# IMM100A register map
Vendor: Infineon; File version: 0.8.0 (Reference Manual v0.8.0)
CPU: CM0 r0p0, little endian, no MPU, no FPU, 2 interrupt priority bits
Registers are 32-bit, read-write, reset 0x0 unless marked. A register's access mark holds for its fields unless they carry their own. Offsets are from the block's base; [hi:lo] are bit positions; {n}, {i} and the like mark numbered series.

## PPB — Cortex-M0 Private Peripheral Block
Base 0xE000E000
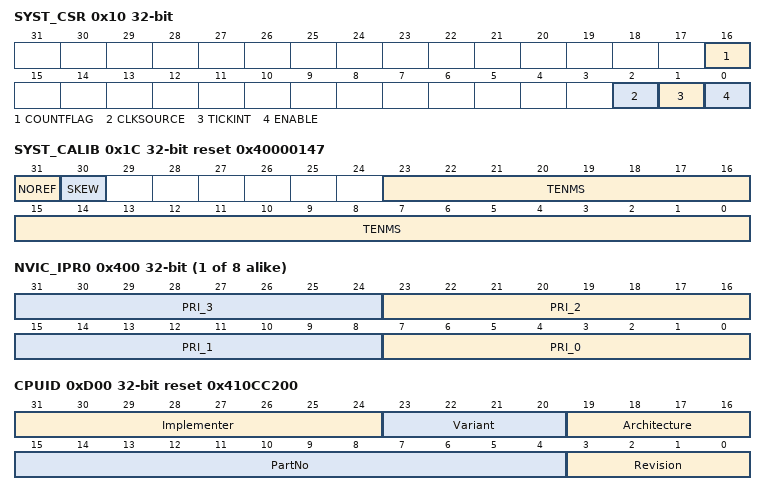
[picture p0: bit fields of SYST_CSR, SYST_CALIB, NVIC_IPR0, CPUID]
0x10 SYST_CSR — SysTick Control and Status Register
  [16] COUNTFLAG — Counter Flag
  [2] CLKSOURCE — Clock Source
    0=External clock; 1=Processor clock
  [1] TICKINT — SysTick Exception Request
    0=Counting down to zero does not assert the SysTick exception request; 1=Counting down to zero to assert the SysTick exception request
  [0] ENABLE — Counter Enable
    0=Counter disabled; 1=Counter enabled
0x14 SYST_RVR reset not defined — SysTick Reload Value Register
  [23:0] RELOAD — Reload Value
0x18 SYST_CVR reset not defined — SysTick Current Value Register
  [23:0] CURRENT — SysTick Counter Current Value
0x1C SYST_CALIB ro reset 0x40000147 — SysTick Calibration Value Register
  [31] NOREF — Reference Clock
  [30] SKEW — Clock Skew
  [23:0] TENMS — 10 Milliseconds
0x100 NVIC_ISER — Interrupt Set-enable Register
  [31:0] SETENA — Interrupt Node Set-enable
    0=Read: Interrupt node disabled. Write: No effect.; 1=Read: Interrupt node enabled. Write: Enable interrupt node
0x180 NVIC_ICER — IInterrupt Clear-enable Register
  [31:0] CLRENA — Interrupt Node Clear-enable
    0=Read: Interrupt node disabled. Write: No effect; 1=Read: Interrupt node enabled. Write: Disable interrupt node.
0x200 NVIC_ISPR — Interrupt Set-pending Register
  [31:0] SETPEND — Interrupt Node Set-pending
    0=Read: Interrupt node is not pending. Write: No effect; 1=Read: Interrupt node is pending. Write: Change interrupt state to pending.
0x280 NVIC_ICPR — Interrupt Clear-pending Register
  [31:0] CLRPEND — Interrupt Node Clear-pending
    0=Read: Interrupt node is not pending. Write: No effect.; 1=Read: Interrupt node is pending. Write: Remove interrupt state from pending.
{0x400+4i} NVIC_IPR{i} (i=0..7) — Interrupt Priority Register {i}
  [8n+7:8n] PRI_{n} (n=0..3) — Priority, Byte Offset {n}
0xD00 CPUID ro reset 0x410CC200 — CPUID Base Register
  [31:24] Implementer — Implementer Code
    65=ARM
  [23:20] Variant — Variant Number
    0=Revision 0
  [19:16] Architecture
    12=ARMv6-M
  [15:4] PartNo — Part Number of the Processor
    0xC20=Cortex-M0
  [3:0] Revision — Revision Number
    0=Patch 0
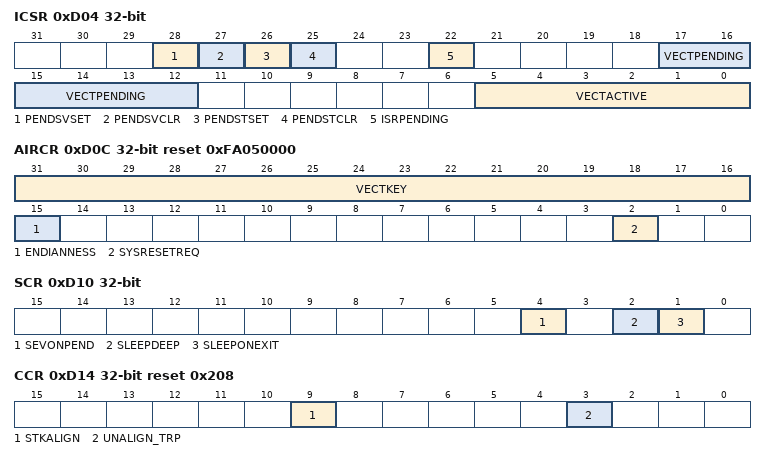
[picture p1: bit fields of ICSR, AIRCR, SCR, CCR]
0xD04 ICSR access per field — Interrupt Control and State Register
  [28] PENDSVSET rw — PendSV Set Pending
    0=PendSV exception is not pending; 1=PendSV excepton is pending
  [27] PENDSVCLR wo — PendSV Clear Pending
    0=Do not clear; 1=Removes pending state from PendSV exception
  [26] PENDSTSET rw — SysTick Exception Set-pending
    0=SysTick exception is not pending; 1=SysTick exception is pending
  [25] PENDSTCLR wo — SysTick Exception Clear-pending
    0=No effect; 1=removes the pending state from the SysTick exception
  [22] ISRPENDING ro — Interrupt Pending Flag
    0=Interrupt not pending; 1=Interrupt pending
  [17:12] VECTPENDING ro — Pending Exception Number
    0=No pending exceptions
  [5:0] VECTACTIVE ro — Active Exception Number
    0=Thread mode
0xD0C AIRCR access per field reset 0xFA050000 — Application Interrupt and Reset Control Register
  [31:16] VECTKEY rw — Register Key
  [15] ENDIANNESS ro — Data Endianness
    0=Little-endian
  [2] SYSRESETREQ wo — System Reset Request
    0=No effect; 1=Requests a system level reset
0xD10 SCR — System Control Register
  [4] SEVONPEND — Send Event on Pending bit
    0=Only enabled interrupts or events can wakeup the processor, disabled interrupts are excluded; 1=Enabled events and all interrupts, including disabled interrupts, can wakeup the processor
  [2] SLEEPDEEP — Low Power Sleep Mode
    0=Sleep; 1=Deep sleep
  [1] SLEEPONEXIT
    0=Do not sleep when returning to Thread mode; 1=Enter sleep, or deep sleep, on return from an ISR to Thread mode
0xD14 CCR ro reset 0x208 — Configuration and Control Register
  [9] STKALIGN — Stack Alignment
  [3] UNALIGN_TRP — Unaligned Access Traps
0xD1C SHPR2 — System Handler Priority Register 2
  [31:24] PRI_11 — Priority of System Handler 11
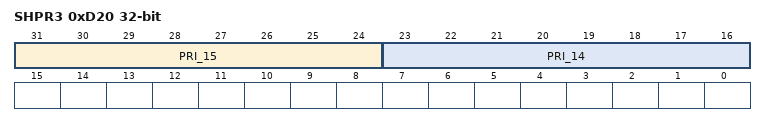
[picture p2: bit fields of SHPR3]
0xD20 SHPR3 — System Handler Priority Register 3
  [31:24] PRI_15 — Priority of System Handler 15
  [23:16] PRI_14 — Priority of System Handler 14
0xD24 SHCSR — System Handler Control and State Register
  [15] SVCALLPENDED — SVCall Pending bit
    0=SVCall is not pending; 1=SVCall is pending

## Notices in the file
Copyright (C) 2017 Infineon Technologies AG. All rights reserved.
Infineon Technologies AG (Infineon) is supplying this software for use with
Infineon's microcontrollers.  This file can be freely distributed within
development tools that are supporting such microcontrollers.
THIS SOFTWARE IS PROVIDED "AS IS".  NO WARRANTIES, WHETHER EXPRESS, IMPLIED
OR STATUTORY, INCLUDING, BUT NOT LIMITED TO, IMPLIED WARRANTIES OF
MERCHANTABILITY AND FITNESS FOR A PARTICULAR PURPOSE APPLY TO THIS SOFTWARE.
INFINEON SHALL NOT, IN ANY CIRCUMSTANCES, BE LIABLE FOR SPECIAL, INCIDENTAL,
OR CONSEQUENTIAL DAMAGES, FOR ANY REASON WHATSOEVER.
